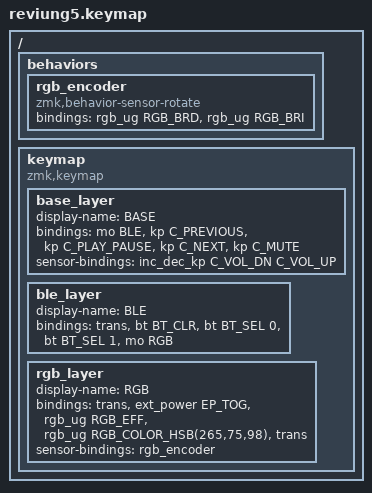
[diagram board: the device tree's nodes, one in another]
/*
 * Copyright (c) 2022 The ZMK Contributors
 *
 * SPDX-License-Identifier: MIT
 */

#include <behaviors.dtsi>
#include <dt-bindings/zmk/keys.h>
#include <dt-bindings/zmk/bt.h>
#include <dt-bindings/zmk/rgb.h>
#include <dt-bindings/zmk/ext_power.h>

#define BASE 0
#define BLE 1
#define RGB 2

/ {
        behaviors {
            rgb_encoder: rgb_encoder {
              compatible = "zmk,behavior-sensor-rotate";
              #sensor-binding-cells = <0>;
              bindings = <&rgb_ug RGB_BRD>, <&rgb_ug RGB_BRI>;
            };
        };

        keymap {
            compatible = "zmk,keymap";

            base_layer {
              display-name = "BASE";
              bindings = <
                // ╭───────────┬─────────────────┬──────────────────┬─────────────┬─────────────╮
                     &mo BLE     &kp C_PREVIOUS    &kp C_PLAY_PAUSE   &kp C_NEXT    &kp C_MUTE
                // ╰───────────┴─────────────────┴──────────────────┴─────────────┴─────────────╯
              >;
              sensor-bindings = <&inc_dec_kp C_VOL_DN C_VOL_UP>;
            };

            ble_layer {
              display-name = "BLE";
              bindings = <
                // ╭───────────┬─────────────┬──────────────┬──────────────┬──────────╮
                     &trans      &bt BT_CLR    &bt BT_SEL 0   &bt BT_SEL 1   &mo RGB
                // ╰───────────┴─────────────┴──────────────┴──────────────┴──────────╯
              >;
            };

            rgb_layer {
              display-name = "RGB";
              bindings = <
                // ╭───────────┬───────────────────┬─────────────────┬──────────────────────────────────┬─────────╮
                     &trans      &ext_power EP_TOG   &rgb_ug RGB_EFF   &rgb_ug RGB_COLOR_HSB(265,75,98)   &trans
                // ╰───────────┴───────────────────┴─────────────────┴──────────────────────────────────┴─────────╯
              >;
              sensor-bindings = <&rgb_encoder>;
            };
        };
};
